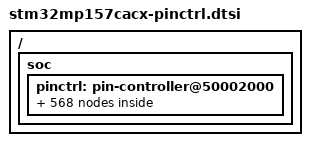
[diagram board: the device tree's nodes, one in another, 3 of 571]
/*
 * NOTE: Autogenerated file using genpinctrl.py
 *
 * SPDX-License-Identifier: Apache-2.0
 */

#include <dt-bindings/pinctrl/stm32-pinctrl.h>

/ {
	soc {
		pinctrl: pin-controller@50002000 {

			/* ADC_IN / ADC_INN / ADC_INP */

			adc1_inp16_pa0: adc1_inp16_pa0 {
				pinmux = <STM32_PINMUX('A', 0, ANALOG)>;
			};

			adc1_inn16_pa1: adc1_inn16_pa1 {
				pinmux = <STM32_PINMUX('A', 1, ANALOG)>;
			};

			adc1_inp17_pa1: adc1_inp17_pa1 {
				pinmux = <STM32_PINMUX('A', 1, ANALOG)>;
			};

			adc1_inp14_pa2: adc1_inp14_pa2 {
				pinmux = <STM32_PINMUX('A', 2, ANALOG)>;
			};

			adc1_inp15_pa3: adc1_inp15_pa3 {
				pinmux = <STM32_PINMUX('A', 3, ANALOG)>;
			};

			adc1_inp18_pa4: adc1_inp18_pa4 {
				pinmux = <STM32_PINMUX('A', 4, ANALOG)>;
			};

			adc1_inn18_pa5: adc1_inn18_pa5 {
				pinmux = <STM32_PINMUX('A', 5, ANALOG)>;
			};

			adc1_inp19_pa5: adc1_inp19_pa5 {
				pinmux = <STM32_PINMUX('A', 5, ANALOG)>;
			};

			adc1_inp3_pa6: adc1_inp3_pa6 {
				pinmux = <STM32_PINMUX('A', 6, ANALOG)>;
			};

			adc1_inn3_pa7: adc1_inn3_pa7 {
				pinmux = <STM32_PINMUX('A', 7, ANALOG)>;
			};

			adc1_inp7_pa7: adc1_inp7_pa7 {
				pinmux = <STM32_PINMUX('A', 7, ANALOG)>;
			};

			adc1_inn5_pb0: adc1_inn5_pb0 {
				pinmux = <STM32_PINMUX('B', 0, ANALOG)>;
			};

			adc1_inp9_pb0: adc1_inp9_pb0 {
				pinmux = <STM32_PINMUX('B', 0, ANALOG)>;
			};

			adc1_inp5_pb1: adc1_inp5_pb1 {
				pinmux = <STM32_PINMUX('B', 1, ANALOG)>;
			};

			adc1_inp10_pc0: adc1_inp10_pc0 {
				pinmux = <STM32_PINMUX('C', 0, ANALOG)>;
			};

			adc1_inn10_pc1: adc1_inn10_pc1 {
				pinmux = <STM32_PINMUX('C', 1, ANALOG)>;
			};

			adc1_inp11_pc1: adc1_inp11_pc1 {
				pinmux = <STM32_PINMUX('C', 1, ANALOG)>;
			};

			adc1_inn11_pc2: adc1_inn11_pc2 {
				pinmux = <STM32_PINMUX('C', 2, ANALOG)>;
			};

			adc1_inp12_pc2: adc1_inp12_pc2 {
				pinmux = <STM32_PINMUX('C', 2, ANALOG)>;
			};

			adc1_inn12_pc3: adc1_inn12_pc3 {
				pinmux = <STM32_PINMUX('C', 3, ANALOG)>;
			};

			adc1_inp13_pc3: adc1_inp13_pc3 {
				pinmux = <STM32_PINMUX('C', 3, ANALOG)>;
			};

			adc1_inp4_pc4: adc1_inp4_pc4 {
				pinmux = <STM32_PINMUX('C', 4, ANALOG)>;
			};

			adc1_inn4_pc5: adc1_inn4_pc5 {
				pinmux = <STM32_PINMUX('C', 5, ANALOG)>;
			};

			adc1_inp8_pc5: adc1_inp8_pc5 {
				pinmux = <STM32_PINMUX('C', 5, ANALOG)>;
			};

			adc1_inp2_pf11: adc1_inp2_pf11 {
				pinmux = <STM32_PINMUX('F', 11, ANALOG)>;
			};

			adc1_inn2_pf12: adc1_inn2_pf12 {
				pinmux = <STM32_PINMUX('F', 12, ANALOG)>;
			};

			adc1_inp6_pf12: adc1_inp6_pf12 {
				pinmux = <STM32_PINMUX('F', 12, ANALOG)>;
			};

			adc2_inp18_pa4: adc2_inp18_pa4 {
				pinmux = <STM32_PINMUX('A', 4, ANALOG)>;
			};

			adc2_inn18_pa5: adc2_inn18_pa5 {
				pinmux = <STM32_PINMUX('A', 5, ANALOG)>;
			};

			adc2_inp19_pa5: adc2_inp19_pa5 {
				pinmux = <STM32_PINMUX('A', 5, ANALOG)>;
			};

			adc2_inp3_pa6: adc2_inp3_pa6 {
				pinmux = <STM32_PINMUX('A', 6, ANALOG)>;
			};

			adc2_inn3_pa7: adc2_inn3_pa7 {
				pinmux = <STM32_PINMUX('A', 7, ANALOG)>;
			};

			adc2_inp7_pa7: adc2_inp7_pa7 {
				pinmux = <STM32_PINMUX('A', 7, ANALOG)>;
			};

			adc2_inn5_pb0: adc2_inn5_pb0 {
				pinmux = <STM32_PINMUX('B', 0, ANALOG)>;
			};

			adc2_inp9_pb0: adc2_inp9_pb0 {
				pinmux = <STM32_PINMUX('B', 0, ANALOG)>;
			};

			adc2_inp5_pb1: adc2_inp5_pb1 {
				pinmux = <STM32_PINMUX('B', 1, ANALOG)>;
			};

			adc2_inp10_pc0: adc2_inp10_pc0 {
				pinmux = <STM32_PINMUX('C', 0, ANALOG)>;
			};

			adc2_inn10_pc1: adc2_inn10_pc1 {
				pinmux = <STM32_PINMUX('C', 1, ANALOG)>;
			};

			adc2_inp11_pc1: adc2_inp11_pc1 {
				pinmux = <STM32_PINMUX('C', 1, ANALOG)>;
			};

			adc2_inp4_pc4: adc2_inp4_pc4 {
				pinmux = <STM32_PINMUX('C', 4, ANALOG)>;
			};

			adc2_inn4_pc5: adc2_inn4_pc5 {
				pinmux = <STM32_PINMUX('C', 5, ANALOG)>;
			};

			adc2_inp8_pc5: adc2_inp8_pc5 {
				pinmux = <STM32_PINMUX('C', 5, ANALOG)>;
			};

			adc2_inp2_pf13: adc2_inp2_pf13 {
				pinmux = <STM32_PINMUX('F', 13, ANALOG)>;
			};

			adc2_inn2_pf14: adc2_inn2_pf14 {
				pinmux = <STM32_PINMUX('F', 14, ANALOG)>;
			};

			adc2_inp6_pf14: adc2_inp6_pf14 {
				pinmux = <STM32_PINMUX('F', 14, ANALOG)>;
			};

			/* DAC_OUT */

			dac1_out1_pa4: dac1_out1_pa4 {
				pinmux = <STM32_PINMUX('A', 4, ANALOG)>;
			};

			dac1_out2_pa5: dac1_out2_pa5 {
				pinmux = <STM32_PINMUX('A', 5, ANALOG)>;
			};

			/* FDCAN_RX */

			fdcan1_rx_pa11: fdcan1_rx_pa11 {
				pinmux = <STM32_PINMUX('A', 11, AF9)>;
			};

			fdcan1_rx_pb8: fdcan1_rx_pb8 {
				pinmux = <STM32_PINMUX('B', 8, AF9)>;
			};

			fdcan1_rx_pd0: fdcan1_rx_pd0 {
				pinmux = <STM32_PINMUX('D', 0, AF9)>;
			};

			fdcan1_rx_ph14: fdcan1_rx_ph14 {
				pinmux = <STM32_PINMUX('H', 14, AF9)>;
			};

			fdcan1_rx_pi9: fdcan1_rx_pi9 {
				pinmux = <STM32_PINMUX('I', 9, AF9)>;
			};

			fdcan2_rx_pb5: fdcan2_rx_pb5 {
				pinmux = <STM32_PINMUX('B', 5, AF9)>;
			};

			fdcan2_rx_pb12: fdcan2_rx_pb12 {
				pinmux = <STM32_PINMUX('B', 12, AF9)>;
			};

			/* FDCAN_TX */

			fdcan1_tx_pa12: fdcan1_tx_pa12 {
				pinmux = <STM32_PINMUX('A', 12, AF9)>;
			};

			fdcan1_tx_pb9: fdcan1_tx_pb9 {
				pinmux = <STM32_PINMUX('B', 9, AF9)>;
			};

			fdcan1_tx_pd1: fdcan1_tx_pd1 {
				pinmux = <STM32_PINMUX('D', 1, AF9)>;
			};

			fdcan1_tx_ph13: fdcan1_tx_ph13 {
				pinmux = <STM32_PINMUX('H', 13, AF9)>;
			};

			fdcan2_tx_pb6: fdcan2_tx_pb6 {
				pinmux = <STM32_PINMUX('B', 6, AF9)>;
			};

			fdcan2_tx_pb13: fdcan2_tx_pb13 {
				pinmux = <STM32_PINMUX('B', 13, AF9)>;
			};

			/* FMC */

			fmc_nl_pb7: fmc_nl_pb7 {
				pinmux = <STM32_PINMUX('B', 7, AF12)>;
				bias-pull-up;
				slew-rate = "very-high-speed";
			};

			fmc_d2_pd0: fmc_d2_pd0 {
				pinmux = <STM32_PINMUX('D', 0, AF12)>;
				bias-pull-up;
				slew-rate = "very-high-speed";
			};

			fmc_d3_pd1: fmc_d3_pd1 {
				pinmux = <STM32_PINMUX('D', 1, AF12)>;
				bias-pull-up;
				slew-rate = "very-high-speed";
			};

			fmc_clk_pd3: fmc_clk_pd3 {
				pinmux = <STM32_PINMUX('D', 3, AF12)>;
				bias-pull-up;
				slew-rate = "very-high-speed";
			};

			fmc_noe_pd4: fmc_noe_pd4 {
				pinmux = <STM32_PINMUX('D', 4, AF12)>;
				bias-pull-up;
				slew-rate = "very-high-speed";
			};

			fmc_nwe_pd5: fmc_nwe_pd5 {
				pinmux = <STM32_PINMUX('D', 5, AF12)>;
				bias-pull-up;
				slew-rate = "very-high-speed";
			};

			fmc_nwait_pd6: fmc_nwait_pd6 {
				pinmux = <STM32_PINMUX('D', 6, AF12)>;
				bias-pull-up;
				slew-rate = "very-high-speed";
			};

			fmc_ne1_pd7: fmc_ne1_pd7 {
				pinmux = <STM32_PINMUX('D', 7, AF12)>;
				bias-pull-up;
				slew-rate = "very-high-speed";
			};

			fmc_d13_pd8: fmc_d13_pd8 {
				pinmux = <STM32_PINMUX('D', 8, AF12)>;
				bias-pull-up;
				slew-rate = "very-high-speed";
			};

			fmc_d14_pd9: fmc_d14_pd9 {
				pinmux = <STM32_PINMUX('D', 9, AF12)>;
				bias-pull-up;
				slew-rate = "very-high-speed";
			};

			fmc_d15_pd10: fmc_d15_pd10 {
				pinmux = <STM32_PINMUX('D', 10, AF12)>;
				bias-pull-up;
				slew-rate = "very-high-speed";
			};

			fmc_a16_pd11: fmc_a16_pd11 {
				pinmux = <STM32_PINMUX('D', 11, AF12)>;
				bias-pull-up;
				slew-rate = "very-high-speed";
			};

			fmc_a17_pd12: fmc_a17_pd12 {
				pinmux = <STM32_PINMUX('D', 12, AF12)>;
				bias-pull-up;
				slew-rate = "very-high-speed";
			};

			fmc_a18_pd13: fmc_a18_pd13 {
				pinmux = <STM32_PINMUX('D', 13, AF12)>;
				bias-pull-up;
				slew-rate = "very-high-speed";
			};

			fmc_d0_pd14: fmc_d0_pd14 {
				pinmux = <STM32_PINMUX('D', 14, AF12)>;
				bias-pull-up;
				slew-rate = "very-high-speed";
			};

			fmc_d1_pd15: fmc_d1_pd15 {
				pinmux = <STM32_PINMUX('D', 15, AF12)>;
				bias-pull-up;
				slew-rate = "very-high-speed";
			};

			fmc_nbl0_pe0: fmc_nbl0_pe0 {
				pinmux = <STM32_PINMUX('E', 0, AF12)>;
				bias-pull-up;
				slew-rate = "very-high-speed";
			};

			fmc_nbl1_pe1: fmc_nbl1_pe1 {
				pinmux = <STM32_PINMUX('E', 1, AF12)>;
				bias-pull-up;
				slew-rate = "very-high-speed";
			};

			fmc_a23_pe2: fmc_a23_pe2 {
				pinmux = <STM32_PINMUX('E', 2, AF12)>;
				bias-pull-up;
				slew-rate = "very-high-speed";
			};

			fmc_a19_pe3: fmc_a19_pe3 {
				pinmux = <STM32_PINMUX('E', 3, AF12)>;
				bias-pull-up;
				slew-rate = "very-high-speed";
			};

			fmc_a20_pe4: fmc_a20_pe4 {
				pinmux = <STM32_PINMUX('E', 4, AF12)>;
				bias-pull-up;
				slew-rate = "very-high-speed";
			};

			fmc_a21_pe5: fmc_a21_pe5 {
				pinmux = <STM32_PINMUX('E', 5, AF12)>;
				bias-pull-up;
				slew-rate = "very-high-speed";
			};

			fmc_a22_pe6: fmc_a22_pe6 {
				pinmux = <STM32_PINMUX('E', 6, AF12)>;
				bias-pull-up;
				slew-rate = "very-high-speed";
			};

			fmc_d4_pe7: fmc_d4_pe7 {
				pinmux = <STM32_PINMUX('E', 7, AF12)>;
				bias-pull-up;
				slew-rate = "very-high-speed";
			};

			fmc_d5_pe8: fmc_d5_pe8 {
				pinmux = <STM32_PINMUX('E', 8, AF12)>;
				bias-pull-up;
				slew-rate = "very-high-speed";
			};

			fmc_d6_pe9: fmc_d6_pe9 {
				pinmux = <STM32_PINMUX('E', 9, AF12)>;
				bias-pull-up;
				slew-rate = "very-high-speed";
			};

			fmc_d7_pe10: fmc_d7_pe10 {
				pinmux = <STM32_PINMUX('E', 10, AF12)>;
				bias-pull-up;
				slew-rate = "very-high-speed";
			};

			fmc_d8_pe11: fmc_d8_pe11 {
				pinmux = <STM32_PINMUX('E', 11, AF12)>;
				bias-pull-up;
				slew-rate = "very-high-speed";
			};

			fmc_d9_pe12: fmc_d9_pe12 {
				pinmux = <STM32_PINMUX('E', 12, AF12)>;
				bias-pull-up;
				slew-rate = "very-high-speed";
			};

			fmc_d10_pe13: fmc_d10_pe13 {
				pinmux = <STM32_PINMUX('E', 13, AF12)>;
				bias-pull-up;
				slew-rate = "very-high-speed";
			};

			fmc_d11_pe14: fmc_d11_pe14 {
				pinmux = <STM32_PINMUX('E', 14, AF12)>;
				bias-pull-up;
				slew-rate = "very-high-speed";
			};

			fmc_d12_pe15: fmc_d12_pe15 {
				pinmux = <STM32_PINMUX('E', 15, AF12)>;
				bias-pull-up;
				slew-rate = "very-high-speed";
			};

			fmc_a0_pf0: fmc_a0_pf0 {
				pinmux = <STM32_PINMUX('F', 0, AF12)>;
				bias-pull-up;
				slew-rate = "very-high-speed";
			};

			fmc_a1_pf1: fmc_a1_pf1 {
				pinmux = <STM32_PINMUX('F', 1, AF12)>;
				bias-pull-up;
				slew-rate = "very-high-speed";
			};

			fmc_a2_pf2: fmc_a2_pf2 {
				pinmux = <STM32_PINMUX('F', 2, AF12)>;
				bias-pull-up;
				slew-rate = "very-high-speed";
			};

			fmc_a3_pf3: fmc_a3_pf3 {
				pinmux = <STM32_PINMUX('F', 3, AF12)>;
				bias-pull-up;
				slew-rate = "very-high-speed";
			};

			fmc_a4_pf4: fmc_a4_pf4 {
				pinmux = <STM32_PINMUX('F', 4, AF12)>;
				bias-pull-up;
				slew-rate = "very-high-speed";
			};

			fmc_a5_pf5: fmc_a5_pf5 {
				pinmux = <STM32_PINMUX('F', 5, AF12)>;
				bias-pull-up;
				slew-rate = "very-high-speed";
			};

			fmc_a6_pf12: fmc_a6_pf12 {
				pinmux = <STM32_PINMUX('F', 12, AF12)>;
				bias-pull-up;
				slew-rate = "very-high-speed";
			};

			fmc_a7_pf13: fmc_a7_pf13 {
				pinmux = <STM32_PINMUX('F', 13, AF12)>;
				bias-pull-up;
				slew-rate = "very-high-speed";
			};

			fmc_a8_pf14: fmc_a8_pf14 {
				pinmux = <STM32_PINMUX('F', 14, AF12)>;
				bias-pull-up;
				slew-rate = "very-high-speed";
			};

			fmc_a9_pf15: fmc_a9_pf15 {
				pinmux = <STM32_PINMUX('F', 15, AF12)>;
				bias-pull-up;
				slew-rate = "very-high-speed";
			};

			fmc_a10_pg0: fmc_a10_pg0 {
				pinmux = <STM32_PINMUX('G', 0, AF12)>;
				bias-pull-up;
				slew-rate = "very-high-speed";
			};

			fmc_a11_pg1: fmc_a11_pg1 {
				pinmux = <STM32_PINMUX('G', 1, AF12)>;
				bias-pull-up;
				slew-rate = "very-high-speed";
			};

			fmc_a12_pg2: fmc_a12_pg2 {
				pinmux = <STM32_PINMUX('G', 2, AF12)>;
				bias-pull-up;
				slew-rate = "very-high-speed";
			};

			fmc_a13_pg3: fmc_a13_pg3 {
				pinmux = <STM32_PINMUX('G', 3, AF12)>;
				bias-pull-up;
				slew-rate = "very-high-speed";
			};

			fmc_a14_pg4: fmc_a14_pg4 {
				pinmux = <STM32_PINMUX('G', 4, AF12)>;
				bias-pull-up;
				slew-rate = "very-high-speed";
			};

			fmc_a15_pg5: fmc_a15_pg5 {
				pinmux = <STM32_PINMUX('G', 5, AF12)>;
				bias-pull-up;
				slew-rate = "very-high-speed";
			};

			fmc_nce_pg9: fmc_nce_pg9 {
				pinmux = <STM32_PINMUX('G', 9, AF12)>;
				bias-pull-up;
				slew-rate = "very-high-speed";
			};

			fmc_ne2_pg9: fmc_ne2_pg9 {
				pinmux = <STM32_PINMUX('G', 9, AF12)>;
				bias-pull-up;
				slew-rate = "very-high-speed";
			};

			fmc_ne3_pg10: fmc_ne3_pg10 {
				pinmux = <STM32_PINMUX('G', 10, AF12)>;
				bias-pull-up;
				slew-rate = "very-high-speed";
			};

			fmc_ne4_pg12: fmc_ne4_pg12 {
				pinmux = <STM32_PINMUX('G', 12, AF12)>;
				bias-pull-up;
				slew-rate = "very-high-speed";
			};

			fmc_a24_pg13: fmc_a24_pg13 {
				pinmux = <STM32_PINMUX('G', 13, AF12)>;
				bias-pull-up;
				slew-rate = "very-high-speed";
			};

			fmc_a25_pg14: fmc_a25_pg14 {
				pinmux = <STM32_PINMUX('G', 14, AF12)>;
				bias-pull-up;
				slew-rate = "very-high-speed";
			};

			/* I2C_SCL */

			i2c1_scl_pb6: i2c1_scl_pb6 {
				pinmux = <STM32_PINMUX('B', 6, AF4)>;
				bias-pull-up;
				drive-open-drain;
			};

			i2c1_scl_pb8: i2c1_scl_pb8 {
				pinmux = <STM32_PINMUX('B', 8, AF4)>;
				bias-pull-up;
				drive-open-drain;
			};

			i2c1_scl_pd12: i2c1_scl_pd12 {
				pinmux = <STM32_PINMUX('D', 12, AF5)>;
				bias-pull-up;
				drive-open-drain;
			};

			i2c1_scl_pf14: i2c1_scl_pf14 {
				pinmux = <STM32_PINMUX('F', 14, AF5)>;
				bias-pull-up;
				drive-open-drain;
			};

			i2c1_scl_ph11: i2c1_scl_ph11 {
				pinmux = <STM32_PINMUX('H', 11, AF5)>;
				bias-pull-up;
				drive-open-drain;
			};

			i2c2_scl_pb10: i2c2_scl_pb10 {
				pinmux = <STM32_PINMUX('B', 10, AF4)>;
				bias-pull-up;
				drive-open-drain;
			};

			i2c2_scl_pd7: i2c2_scl_pd7 {
				pinmux = <STM32_PINMUX('D', 7, AF4)>;
				bias-pull-up;
				drive-open-drain;
			};

			i2c2_scl_pf1: i2c2_scl_pf1 {
				pinmux = <STM32_PINMUX('F', 1, AF4)>;
				bias-pull-up;
				drive-open-drain;
			};

			i2c2_scl_ph4: i2c2_scl_ph4 {
				pinmux = <STM32_PINMUX('H', 4, AF4)>;
				bias-pull-up;
				drive-open-drain;
			};

			i2c2_scl_pz0: i2c2_scl_pz0 {
				pinmux = <STM32_PINMUX('Z', 0, AF3)>;
				bias-pull-up;
				drive-open-drain;
			};

			i2c2_scl_pz2: i2c2_scl_pz2 {
				pinmux = <STM32_PINMUX('Z', 2, AF3)>;
				bias-pull-up;
				drive-open-drain;
			};

			i2c2_scl_pz4: i2c2_scl_pz4 {
				pinmux = <STM32_PINMUX('Z', 4, AF3)>;
				bias-pull-up;
				drive-open-drain;
			};

			i2c2_scl_pz6: i2c2_scl_pz6 {
				pinmux = <STM32_PINMUX('Z', 6, AF3)>;
				bias-pull-up;
				drive-open-drain;
			};

			i2c3_scl_pa8: i2c3_scl_pa8 {
				pinmux = <STM32_PINMUX('A', 8, AF4)>;
				bias-pull-up;
				drive-open-drain;
			};

			i2c3_scl_ph7: i2c3_scl_ph7 {
				pinmux = <STM32_PINMUX('H', 7, AF4)>;
				bias-pull-up;
				drive-open-drain;
			};

			i2c4_scl_pb6: i2c4_scl_pb6 {
				pinmux = <STM32_PINMUX('B', 6, AF6)>;
				bias-pull-up;
				drive-open-drain;
			};

			i2c4_scl_pb8: i2c4_scl_pb8 {
				pinmux = <STM32_PINMUX('B', 8, AF6)>;
				bias-pull-up;
				drive-open-drain;
			};

			i2c4_scl_pd12: i2c4_scl_pd12 {
				pinmux = <STM32_PINMUX('D', 12, AF4)>;
				bias-pull-up;
				drive-open-drain;
			};

			i2c4_scl_pe2: i2c4_scl_pe2 {
				pinmux = <STM32_PINMUX('E', 2, AF4)>;
				bias-pull-up;
				drive-open-drain;
			};

			i2c4_scl_pf14: i2c4_scl_pf14 {
				pinmux = <STM32_PINMUX('F', 14, AF4)>;
				bias-pull-up;
				drive-open-drain;
			};

			i2c4_scl_ph11: i2c4_scl_ph11 {
				pinmux = <STM32_PINMUX('H', 11, AF4)>;
				bias-pull-up;
				drive-open-drain;
			};

			i2c4_scl_pz4: i2c4_scl_pz4 {
				pinmux = <STM32_PINMUX('Z', 4, AF6)>;
				bias-pull-up;
				drive-open-drain;
			};

			i2c5_scl_pa11: i2c5_scl_pa11 {
				pinmux = <STM32_PINMUX('A', 11, AF4)>;
				bias-pull-up;
				drive-open-drain;
			};

			i2c5_scl_pd1: i2c5_scl_pd1 {
				pinmux = <STM32_PINMUX('D', 1, AF4)>;
				bias-pull-up;
				drive-open-drain;
			};

			i2c5_scl_pz4: i2c5_scl_pz4 {
				pinmux = <STM32_PINMUX('Z', 4, AF4)>;
				bias-pull-up;
				drive-open-drain;
			};

			i2c6_scl_pa11: i2c6_scl_pa11 {
				pinmux = <STM32_PINMUX('A', 11, AF2)>;
				bias-pull-up;
				drive-open-drain;
			};

			i2c6_scl_pd1: i2c6_scl_pd1 {
				pinmux = <STM32_PINMUX('D', 1, AF2)>;
				bias-pull-up;
				drive-open-drain;
			};

			i2c6_scl_pz0: i2c6_scl_pz0 {
				pinmux = <STM32_PINMUX('Z', 0, AF2)>;
				bias-pull-up;
				drive-open-drain;
			};

			i2c6_scl_pz2: i2c6_scl_pz2 {
				pinmux = <STM32_PINMUX('Z', 2, AF2)>;
				bias-pull-up;
				drive-open-drain;
			};

			i2c6_scl_pz4: i2c6_scl_pz4 {
				pinmux = <STM32_PINMUX('Z', 4, AF2)>;
				bias-pull-up;
				drive-open-drain;
			};

			i2c6_scl_pz6: i2c6_scl_pz6 {
				pinmux = <STM32_PINMUX('Z', 6, AF2)>;
				bias-pull-up;
				drive-open-drain;
			};

			/* I2C_SDA */

			i2c1_sda_pb7: i2c1_sda_pb7 {
				pinmux = <STM32_PINMUX('B', 7, AF4)>;
				bias-pull-up;
				drive-open-drain;
			};

			i2c1_sda_pb9: i2c1_sda_pb9 {
				pinmux = <STM32_PINMUX('B', 9, AF4)>;
				bias-pull-up;
				drive-open-drain;
			};

			i2c1_sda_pd13: i2c1_sda_pd13 {
				pinmux = <STM32_PINMUX('D', 13, AF5)>;
				bias-pull-up;
				drive-open-drain;
			};

			i2c1_sda_pf15: i2c1_sda_pf15 {
				pinmux = <STM32_PINMUX('F', 15, AF5)>;
				bias-pull-up;
				drive-open-drain;
			};

			i2c1_sda_ph12: i2c1_sda_ph12 {
				pinmux = <STM32_PINMUX('H', 12, AF5)>;
				bias-pull-up;
				drive-open-drain;
			};

			i2c2_sda_pb11: i2c2_sda_pb11 {
				pinmux = <STM32_PINMUX('B', 11, AF4)>;
				bias-pull-up;
				drive-open-drain;
			};

			i2c2_sda_pf0: i2c2_sda_pf0 {
				pinmux = <STM32_PINMUX('F', 0, AF4)>;
				bias-pull-up;
				drive-open-drain;
			};

			i2c2_sda_pg15: i2c2_sda_pg15 {
				pinmux = <STM32_PINMUX('G', 15, AF4)>;
				bias-pull-up;
				drive-open-drain;
			};

			i2c2_sda_ph5: i2c2_sda_ph5 {
				pinmux = <STM32_PINMUX('H', 5, AF4)>;
				bias-pull-up;
				drive-open-drain;
			};

			i2c2_sda_pz1: i2c2_sda_pz1 {
				pinmux = <STM32_PINMUX('Z', 1, AF3)>;
				bias-pull-up;
				drive-open-drain;
			};

			i2c2_sda_pz3: i2c2_sda_pz3 {
				pinmux = <STM32_PINMUX('Z', 3, AF3)>;
				bias-pull-up;
				drive-open-drain;
			};

			i2c2_sda_pz5: i2c2_sda_pz5 {
				pinmux = <STM32_PINMUX('Z', 5, AF3)>;
				bias-pull-up;
				drive-open-drain;
			};

			i2c2_sda_pz7: i2c2_sda_pz7 {
				pinmux = <STM32_PINMUX('Z', 7, AF3)>;
				bias-pull-up;
				drive-open-drain;
			};

			i2c3_sda_pc9: i2c3_sda_pc9 {
				pinmux = <STM32_PINMUX('C', 9, AF4)>;
				bias-pull-up;
				drive-open-drain;
			};

			i2c3_sda_ph8: i2c3_sda_ph8 {
				pinmux = <STM32_PINMUX('H', 8, AF4)>;
				bias-pull-up;
				drive-open-drain;
			};

			i2c4_sda_pb7: i2c4_sda_pb7 {
				pinmux = <STM32_PINMUX('B', 7, AF6)>;
				bias-pull-up;
				drive-open-drain;
			};

			i2c4_sda_pb9: i2c4_sda_pb9 {
				pinmux = <STM32_PINMUX('B', 9, AF6)>;
				bias-pull-up;
				drive-open-drain;
			};

			i2c4_sda_pd13: i2c4_sda_pd13 {
				pinmux = <STM32_PINMUX('D', 13, AF4)>;
				bias-pull-up;
				drive-open-drain;
			};

			i2c4_sda_pf15: i2c4_sda_pf15 {
				pinmux = <STM32_PINMUX('F', 15, AF4)>;
				bias-pull-up;
				drive-open-drain;
			};

			i2c4_sda_ph12: i2c4_sda_ph12 {
				pinmux = <STM32_PINMUX('H', 12, AF4)>;
				bias-pull-up;
				drive-open-drain;
			};

			i2c4_sda_pz1: i2c4_sda_pz1 {
				pinmux = <STM32_PINMUX('Z', 1, AF6)>;
				bias-pull-up;
				drive-open-drain;
			};

			i2c4_sda_pz3: i2c4_sda_pz3 {
				pinmux = <STM32_PINMUX('Z', 3, AF6)>;
				bias-pull-up;
				drive-open-drain;
			};

			i2c4_sda_pz5: i2c4_sda_pz5 {
				pinmux = <STM32_PINMUX('Z', 5, AF6)>;
				bias-pull-up;
				drive-open-drain;
			};

			i2c5_sda_pa12: i2c5_sda_pa12 {
				pinmux = <STM32_PINMUX('A', 12, AF4)>;
				bias-pull-up;
				drive-open-drain;
			};

			i2c5_sda_pd0: i2c5_sda_pd0 {
				pinmux = <STM32_PINMUX('D', 0, AF4)>;
				bias-pull-up;
				drive-open-drain;
			};

			i2c5_sda_pz1: i2c5_sda_pz1 {
				pinmux = <STM32_PINMUX('Z', 1, AF4)>;
				bias-pull-up;
				drive-open-drain;
			};

			i2c5_sda_pz3: i2c5_sda_pz3 {
				pinmux = <STM32_PINMUX('Z', 3, AF4)>;
				bias-pull-up;
				drive-open-drain;
			};

			i2c5_sda_pz5: i2c5_sda_pz5 {
				pinmux = <STM32_PINMUX('Z', 5, AF4)>;
				bias-pull-up;
				drive-open-drain;
			};

			i2c6_sda_pa12: i2c6_sda_pa12 {
				pinmux = <STM32_PINMUX('A', 12, AF2)>;
				bias-pull-up;
				drive-open-drain;
			};

			i2c6_sda_pd0: i2c6_sda_pd0 {
				pinmux = <STM32_PINMUX('D', 0, AF2)>;
				bias-pull-up;
				drive-open-drain;
			};

			i2c6_sda_pz1: i2c6_sda_pz1 {
				pinmux = <STM32_PINMUX('Z', 1, AF2)>;
				bias-pull-up;
				drive-open-drain;
			};

			i2c6_sda_pz3: i2c6_sda_pz3 {
				pinmux = <STM32_PINMUX('Z', 3, AF2)>;
				bias-pull-up;
				drive-open-drain;
			};

			i2c6_sda_pz5: i2c6_sda_pz5 {
				pinmux = <STM32_PINMUX('Z', 5, AF2)>;
				bias-pull-up;
				drive-open-drain;
			};

			i2c6_sda_pz7: i2c6_sda_pz7 {
				pinmux = <STM32_PINMUX('Z', 7, AF2)>;
				bias-pull-up;
				drive-open-drain;
			};

			/* I2S_CK */

			i2s1_ck_pa5: i2s1_ck_pa5 {
				pinmux = <STM32_PINMUX('A', 5, AF5)>;
				slew-rate = "very-high-speed";
			};

			i2s1_ck_pb3: i2s1_ck_pb3 {
				pinmux = <STM32_PINMUX('B', 3, AF5)>;
				slew-rate = "very-high-speed";
			};

			i2s1_ck_pz0: i2s1_ck_pz0 {
				pinmux = <STM32_PINMUX('Z', 0, AF5)>;
				slew-rate = "very-high-speed";
			};

			i2s2_ck_pa9: i2s2_ck_pa9 {
				pinmux = <STM32_PINMUX('A', 9, AF5)>;
				slew-rate = "very-high-speed";
			};

			i2s2_ck_pb10: i2s2_ck_pb10 {
				pinmux = <STM32_PINMUX('B', 10, AF5)>;
				slew-rate = "very-high-speed";
			};

			i2s2_ck_pb13: i2s2_ck_pb13 {
				pinmux = <STM32_PINMUX('B', 13, AF5)>;
				slew-rate = "very-high-speed";
			};

			i2s2_ck_pd3: i2s2_ck_pd3 {
				pinmux = <STM32_PINMUX('D', 3, AF5)>;
				slew-rate = "very-high-speed";
			};

			i2s2_ck_pi1: i2s2_ck_pi1 {
				pinmux = <STM32_PINMUX('I', 1, AF5)>;
				slew-rate = "very-high-speed";
			};

			i2s3_ck_pb3: i2s3_ck_pb3 {
				pinmux = <STM32_PINMUX('B', 3, AF6)>;
				slew-rate = "very-high-speed";
			};

			i2s3_ck_pc10: i2s3_ck_pc10 {
				pinmux = <STM32_PINMUX('C', 10, AF6)>;
				slew-rate = "very-high-speed";
			};

			i2s3_ck_pe0: i2s3_ck_pe0 {
				pinmux = <STM32_PINMUX('E', 0, AF5)>;
				slew-rate = "very-high-speed";
			};

			/* I2S_WS */

			i2s1_ws_pa4: i2s1_ws_pa4 {
				pinmux = <STM32_PINMUX('A', 4, AF5)>;
			};

			i2s1_ws_pa15: i2s1_ws_pa15 {
				pinmux = <STM32_PINMUX('A', 15, AF5)>;
			};

			i2s1_ws_pz3: i2s1_ws_pz3 {
				pinmux = <STM32_PINMUX('Z', 3, AF5)>;
			};

			i2s2_ws_pa11: i2s2_ws_pa11 {
				pinmux = <STM32_PINMUX('A', 11, AF5)>;
			};

			i2s2_ws_pb4: i2s2_ws_pb4 {
				pinmux = <STM32_PINMUX('B', 4, AF7)>;
			};

			i2s2_ws_pb9: i2s2_ws_pb9 {
				pinmux = <STM32_PINMUX('B', 9, AF5)>;
			};

			i2s2_ws_pb12: i2s2_ws_pb12 {
				pinmux = <STM32_PINMUX('B', 12, AF5)>;
			};

			i2s2_ws_pi0: i2s2_ws_pi0 {
				pinmux = <STM32_PINMUX('I', 0, AF5)>;
			};

			i2s3_ws_pa4: i2s3_ws_pa4 {
				pinmux = <STM32_PINMUX('A', 4, AF6)>;
			};

			i2s3_ws_pa10: i2s3_ws_pa10 {
				pinmux = <STM32_PINMUX('A', 10, AF5)>;
			};

			i2s3_ws_pa15: i2s3_ws_pa15 {
				pinmux = <STM32_PINMUX('A', 15, AF6)>;
			};

			/* QUADSPI */

			quadspi_bk1_io3_pa1: quadspi_bk1_io3_pa1 {
				pinmux = <STM32_PINMUX('A', 1, AF9)>;
				slew-rate = "very-high-speed";
			};

			quadspi_clk_pa7: quadspi_clk_pa7 {
				pinmux = <STM32_PINMUX('A', 7, AF10)>;
				slew-rate = "very-high-speed";
			};

			quadspi_clk_pb2: quadspi_clk_pb2 {
				pinmux = <STM32_PINMUX('B', 2, AF9)>;
				slew-rate = "very-high-speed";
			};

			quadspi_bk1_ncs_pb6: quadspi_bk1_ncs_pb6 {
				pinmux = <STM32_PINMUX('B', 6, AF10)>;
				slew-rate = "very-high-speed";
			};

			quadspi_bk1_ncs_pb10: quadspi_bk1_ncs_pb10 {
				pinmux = <STM32_PINMUX('B', 10, AF9)>;
				slew-rate = "very-high-speed";
			};

			quadspi_bk2_ncs_pc0: quadspi_bk2_ncs_pc0 {
				pinmux = <STM32_PINMUX('C', 0, AF10)>;
				slew-rate = "very-high-speed";
			};

			quadspi_bk1_io0_pc9: quadspi_bk1_io0_pc9 {
				pinmux = <STM32_PINMUX('C', 9, AF9)>;
				slew-rate = "very-high-speed";
			};

			quadspi_bk1_io1_pc10: quadspi_bk1_io1_pc10 {
				pinmux = <STM32_PINMUX('C', 10, AF9)>;
				slew-rate = "very-high-speed";
			};

			quadspi_bk2_ncs_pc11: quadspi_bk2_ncs_pc11 {
				pinmux = <STM32_PINMUX('C', 11, AF9)>;
				slew-rate = "very-high-speed";
			};

			quadspi_bk1_io0_pd11: quadspi_bk1_io0_pd11 {
				pinmux = <STM32_PINMUX('D', 11, AF9)>;
				slew-rate = "very-high-speed";
			};

			quadspi_bk1_io1_pd12: quadspi_bk1_io1_pd12 {
				pinmux = <STM32_PINMUX('D', 12, AF9)>;
				slew-rate = "very-high-speed";
			};

			quadspi_bk1_io3_pd13: quadspi_bk1_io3_pd13 {
				pinmux = <STM32_PINMUX('D', 13, AF9)>;
				slew-rate = "very-high-speed";
			};

			quadspi_bk1_io2_pe2: quadspi_bk1_io2_pe2 {
				pinmux = <STM32_PINMUX('E', 2, AF9)>;
				slew-rate = "very-high-speed";
			};

			quadspi_bk2_io0_pe7: quadspi_bk2_io0_pe7 {
				pinmux = <STM32_PINMUX('E', 7, AF10)>;
				slew-rate = "very-high-speed";
			};

			quadspi_bk2_io1_pe8: quadspi_bk2_io1_pe8 {
				pinmux = <STM32_PINMUX('E', 8, AF10)>;
				slew-rate = "very-high-speed";
			};

			quadspi_bk2_io2_pe9: quadspi_bk2_io2_pe9 {
				pinmux = <STM32_PINMUX('E', 9, AF10)>;
				slew-rate = "very-high-speed";
			};

			quadspi_bk2_io3_pe10: quadspi_bk2_io3_pe10 {
				pinmux = <STM32_PINMUX('E', 10, AF10)>;
				slew-rate = "very-high-speed";
			};

			quadspi_bk1_io3_pf6: quadspi_bk1_io3_pf6 {
				pinmux = <STM32_PINMUX('F', 6, AF9)>;
				slew-rate = "very-high-speed";
			};

			quadspi_bk1_io2_pf7: quadspi_bk1_io2_pf7 {
				pinmux = <STM32_PINMUX('F', 7, AF9)>;
				slew-rate = "very-high-speed";
			};

			quadspi_bk1_io0_pf8: quadspi_bk1_io0_pf8 {
				pinmux = <STM32_PINMUX('F', 8, AF10)>;
				slew-rate = "very-high-speed";
			};

			quadspi_bk1_io1_pf9: quadspi_bk1_io1_pf9 {
				pinmux = <STM32_PINMUX('F', 9, AF10)>;
				slew-rate = "very-high-speed";
			};

			quadspi_clk_pf10: quadspi_clk_pf10 {
				pinmux = <STM32_PINMUX('F', 10, AF9)>;
				slew-rate = "very-high-speed";
			};

			quadspi_bk2_io3_pg7: quadspi_bk2_io3_pg7 {
				pinmux = <STM32_PINMUX('G', 7, AF11)>;
				slew-rate = "very-high-speed";
			};

			quadspi_clk_pg7: quadspi_clk_pg7 {
				pinmux = <STM32_PINMUX('G', 7, AF9)>;
				slew-rate = "very-high-speed";
			};

			quadspi_bk2_io2_pg9: quadspi_bk2_io2_pg9 {
				pinmux = <STM32_PINMUX('G', 9, AF9)>;
				slew-rate = "very-high-speed";
			};

			quadspi_bk2_io2_pg10: quadspi_bk2_io2_pg10 {
				pinmux = <STM32_PINMUX('G', 10, AF11)>;
				slew-rate = "very-high-speed";
			};

			quadspi_bk2_io3_pg14: quadspi_bk2_io3_pg14 {
				pinmux = <STM32_PINMUX('G', 14, AF9)>;
				slew-rate = "very-high-speed";
			};

			quadspi_bk2_io0_ph2: quadspi_bk2_io0_ph2 {
				pinmux = <STM32_PINMUX('H', 2, AF9)>;
				slew-rate = "very-high-speed";
			};

			quadspi_bk2_io1_ph3: quadspi_bk2_io1_ph3 {
				pinmux = <STM32_PINMUX('H', 3, AF9)>;
				slew-rate = "very-high-speed";
			};

			/* SDMMC */

			sdmmc1_cdir_pa15: sdmmc1_cdir_pa15 {
				pinmux = <STM32_PINMUX('A', 15, AF3)>;
				slew-rate = "very-high-speed";
			};

			sdmmc1_d5_pa15: sdmmc1_d5_pa15 {
				pinmux = <STM32_PINMUX('A', 15, AF11)>;
				slew-rate = "very-high-speed";
			};

			sdmmc1_ckin_pb8: sdmmc1_ckin_pb8 {
				pinmux = <STM32_PINMUX('B', 8, AF5)>;
				slew-rate = "very-high-speed";
			};

			sdmmc1_d4_pb8: sdmmc1_d4_pb8 {
				pinmux = <STM32_PINMUX('B', 8, AF12)>;
				slew-rate = "very-high-speed";
			};

			sdmmc1_cdir_pb9: sdmmc1_cdir_pb9 {
				pinmux = <STM32_PINMUX('B', 9, AF11)>;
				slew-rate = "very-high-speed";
			};

			sdmmc1_d5_pb9: sdmmc1_d5_pb9 {
				pinmux = <STM32_PINMUX('B', 9, AF12)>;
				slew-rate = "very-high-speed";
			};

			sdmmc1_d0dir_pc6: sdmmc1_d0dir_pc6 {
				pinmux = <STM32_PINMUX('C', 6, AF8)>;
				slew-rate = "very-high-speed";
			};

			sdmmc1_d6_pc6: sdmmc1_d6_pc6 {
				pinmux = <STM32_PINMUX('C', 6, AF12)>;
				slew-rate = "very-high-speed";
			};

			sdmmc1_d123dir_pc7: sdmmc1_d123dir_pc7 {
				pinmux = <STM32_PINMUX('C', 7, AF8)>;
				slew-rate = "very-high-speed";
			};

			sdmmc1_d7_pc7: sdmmc1_d7_pc7 {
				pinmux = <STM32_PINMUX('C', 7, AF12)>;
				slew-rate = "very-high-speed";
			};

			sdmmc1_d0_pc8: sdmmc1_d0_pc8 {
				pinmux = <STM32_PINMUX('C', 8, AF12)>;
				slew-rate = "very-high-speed";
			};

			sdmmc1_d1_pc9: sdmmc1_d1_pc9 {
				pinmux = <STM32_PINMUX('C', 9, AF12)>;
				slew-rate = "very-high-speed";
			};

			sdmmc1_d2_pc10: sdmmc1_d2_pc10 {
				pinmux = <STM32_PINMUX('C', 10, AF12)>;
				slew-rate = "very-high-speed";
			};

			sdmmc1_d3_pc11: sdmmc1_d3_pc11 {
				pinmux = <STM32_PINMUX('C', 11, AF12)>;
				slew-rate = "very-high-speed";
			};

			sdmmc1_ck_pc12: sdmmc1_ck_pc12 {
				pinmux = <STM32_PINMUX('C', 12, AF12)>;
				slew-rate = "very-high-speed";
			};

			sdmmc1_cmd_pd2: sdmmc1_cmd_pd2 {
				pinmux = <STM32_PINMUX('D', 2, AF12)>;
				slew-rate = "very-high-speed";
			};

			sdmmc1_d123dir_pd3: sdmmc1_d123dir_pd3 {
				pinmux = <STM32_PINMUX('D', 3, AF8)>;
				slew-rate = "very-high-speed";
			};

			sdmmc1_d7_pd3: sdmmc1_d7_pd3 {
				pinmux = <STM32_PINMUX('D', 3, AF11)>;
				slew-rate = "very-high-speed";
			};

			sdmmc1_ckin_pe4: sdmmc1_ckin_pe4 {
				pinmux = <STM32_PINMUX('E', 4, AF8)>;
				slew-rate = "very-high-speed";
			};

			sdmmc1_d4_pe4: sdmmc1_d4_pe4 {
				pinmux = <STM32_PINMUX('E', 4, AF11)>;
				slew-rate = "very-high-speed";
			};

			sdmmc1_d0dir_pe5: sdmmc1_d0dir_pe5 {
				pinmux = <STM32_PINMUX('E', 5, AF8)>;
				slew-rate = "very-high-speed";
			};

			sdmmc1_d6_pe5: sdmmc1_d6_pe5 {
				pinmux = <STM32_PINMUX('E', 5, AF11)>;
				slew-rate = "very-high-speed";
			};

			sdmmc1_d2_pe6: sdmmc1_d2_pe6 {
				pinmux = <STM32_PINMUX('E', 6, AF8)>;
				slew-rate = "very-high-speed";
			};

			sdmmc1_d0dir_pe12: sdmmc1_d0dir_pe12 {
				pinmux = <STM32_PINMUX('E', 12, AF8)>;
				slew-rate = "very-high-speed";
			};

			sdmmc1_d123dir_pe14: sdmmc1_d123dir_pe14 {
				pinmux = <STM32_PINMUX('E', 14, AF11)>;
				slew-rate = "very-high-speed";
			};

			sdmmc1_d0dir_pf2: sdmmc1_d0dir_pf2 {
				pinmux = <STM32_PINMUX('F', 2, AF11)>;
				slew-rate = "very-high-speed";
			};

			sdmmc2_cmd_pa0: sdmmc2_cmd_pa0 {
				pinmux = <STM32_PINMUX('A', 0, AF9)>;
				slew-rate = "very-high-speed";
			};

			sdmmc2_d0dir_pa2: sdmmc2_d0dir_pa2 {
				pinmux = <STM32_PINMUX('A', 2, AF10)>;
				slew-rate = "very-high-speed";
			};

			sdmmc2_ckin_pa8: sdmmc2_ckin_pa8 {
				pinmux = <STM32_PINMUX('A', 8, AF8)>;
				slew-rate = "very-high-speed";
			};

			sdmmc2_d4_pa8: sdmmc2_d4_pa8 {
				pinmux = <STM32_PINMUX('A', 8, AF9)>;
				slew-rate = "very-high-speed";
			};

			sdmmc2_cdir_pa9: sdmmc2_cdir_pa9 {
				pinmux = <STM32_PINMUX('A', 9, AF8)>;
				slew-rate = "very-high-speed";
			};

			sdmmc2_d5_pa9: sdmmc2_d5_pa9 {
				pinmux = <STM32_PINMUX('A', 9, AF10)>;
				slew-rate = "very-high-speed";
			};

			sdmmc2_cdir_pa15: sdmmc2_cdir_pa15 {
				pinmux = <STM32_PINMUX('A', 15, AF10)>;
				slew-rate = "very-high-speed";
			};

			sdmmc2_d5_pa15: sdmmc2_d5_pa15 {
				pinmux = <STM32_PINMUX('A', 15, AF9)>;
				slew-rate = "very-high-speed";
			};

			sdmmc2_d2_pb3: sdmmc2_d2_pb3 {
				pinmux = <STM32_PINMUX('B', 3, AF9)>;
				slew-rate = "very-high-speed";
			};

			sdmmc2_d3_pb4: sdmmc2_d3_pb4 {
				pinmux = <STM32_PINMUX('B', 4, AF9)>;
				slew-rate = "very-high-speed";
			};

			sdmmc2_d1_pb7: sdmmc2_d1_pb7 {
				pinmux = <STM32_PINMUX('B', 7, AF10)>;
				slew-rate = "very-high-speed";
			};

			sdmmc2_ckin_pb8: sdmmc2_ckin_pb8 {
				pinmux = <STM32_PINMUX('B', 8, AF7)>;
				slew-rate = "very-high-speed";
			};

			sdmmc2_d4_pb8: sdmmc2_d4_pb8 {
				pinmux = <STM32_PINMUX('B', 8, AF10)>;
				slew-rate = "very-high-speed";
			};

			sdmmc2_cdir_pb9: sdmmc2_cdir_pb9 {
				pinmux = <STM32_PINMUX('B', 9, AF7)>;
				slew-rate = "very-high-speed";
			};

			sdmmc2_d5_pb9: sdmmc2_d5_pb9 {
				pinmux = <STM32_PINMUX('B', 9, AF10)>;
				slew-rate = "very-high-speed";
			};

			sdmmc2_d0_pb14: sdmmc2_d0_pb14 {
				pinmux = <STM32_PINMUX('B', 14, AF9)>;
				slew-rate = "very-high-speed";
			};

			sdmmc2_d1_pb15: sdmmc2_d1_pb15 {
				pinmux = <STM32_PINMUX('B', 15, AF9)>;
				slew-rate = "very-high-speed";
			};

			sdmmc2_ck_pc1: sdmmc2_ck_pc1 {
				pinmux = <STM32_PINMUX('C', 1, AF9)>;
				slew-rate = "very-high-speed";
			};

			sdmmc2_d0dir_pc6: sdmmc2_d0dir_pc6 {
				pinmux = <STM32_PINMUX('C', 6, AF9)>;
				slew-rate = "very-high-speed";
			};

			sdmmc2_d6_pc6: sdmmc2_d6_pc6 {
				pinmux = <STM32_PINMUX('C', 6, AF10)>;
				slew-rate = "very-high-speed";
			};

			sdmmc2_d123dir_pc7: sdmmc2_d123dir_pc7 {
				pinmux = <STM32_PINMUX('C', 7, AF9)>;
				slew-rate = "very-high-speed";
			};

			sdmmc2_d7_pc7: sdmmc2_d7_pc7 {
				pinmux = <STM32_PINMUX('C', 7, AF10)>;
				slew-rate = "very-high-speed";
			};

			sdmmc2_d123dir_pd3: sdmmc2_d123dir_pd3 {
				pinmux = <STM32_PINMUX('D', 3, AF10)>;
				slew-rate = "very-high-speed";
			};

			sdmmc2_d7_pd3: sdmmc2_d7_pd3 {
				pinmux = <STM32_PINMUX('D', 3, AF9)>;
				slew-rate = "very-high-speed";
			};

			sdmmc2_ck_pe3: sdmmc2_ck_pe3 {
				pinmux = <STM32_PINMUX('E', 3, AF9)>;
				slew-rate = "very-high-speed";
			};

			sdmmc2_ckin_pe4: sdmmc2_ckin_pe4 {
				pinmux = <STM32_PINMUX('E', 4, AF7)>;
				slew-rate = "very-high-speed";
			};

			sdmmc2_d4_pe4: sdmmc2_d4_pe4 {
				pinmux = <STM32_PINMUX('E', 4, AF9)>;
				slew-rate = "very-high-speed";
			};

			sdmmc2_d0dir_pe5: sdmmc2_d0dir_pe5 {
				pinmux = <STM32_PINMUX('E', 5, AF7)>;
				slew-rate = "very-high-speed";
			};

			sdmmc2_d6_pe5: sdmmc2_d6_pe5 {
				pinmux = <STM32_PINMUX('E', 5, AF9)>;
				slew-rate = "very-high-speed";
			};

			sdmmc2_d0_pe6: sdmmc2_d0_pe6 {
				pinmux = <STM32_PINMUX('E', 6, AF7)>;
				slew-rate = "very-high-speed";
			};

			sdmmc2_d0dir_pf2: sdmmc2_d0dir_pf2 {
				pinmux = <STM32_PINMUX('F', 2, AF9)>;
				slew-rate = "very-high-speed";
			};

			sdmmc2_cmd_pg6: sdmmc2_cmd_pg6 {
				pinmux = <STM32_PINMUX('G', 6, AF10)>;
				slew-rate = "very-high-speed";
			};

			sdmmc3_cmd_pd0: sdmmc3_cmd_pd0 {
				pinmux = <STM32_PINMUX('D', 0, AF10)>;
				slew-rate = "very-high-speed";
			};

			sdmmc3_d0_pd1: sdmmc3_d0_pd1 {
				pinmux = <STM32_PINMUX('D', 1, AF10)>;
				slew-rate = "very-high-speed";
			};

			sdmmc3_d1_pd4: sdmmc3_d1_pd4 {
				pinmux = <STM32_PINMUX('D', 4, AF10)>;
				slew-rate = "very-high-speed";
			};

			sdmmc3_d2_pd5: sdmmc3_d2_pd5 {
				pinmux = <STM32_PINMUX('D', 5, AF10)>;
				slew-rate = "very-high-speed";
			};

			sdmmc3_d3_pd7: sdmmc3_d3_pd7 {
				pinmux = <STM32_PINMUX('D', 7, AF10)>;
				slew-rate = "very-high-speed";
			};

			sdmmc3_ckin_pf0: sdmmc3_ckin_pf0 {
				pinmux = <STM32_PINMUX('F', 0, AF10)>;
				slew-rate = "very-high-speed";
			};

			sdmmc3_d0_pf0: sdmmc3_d0_pf0 {
				pinmux = <STM32_PINMUX('F', 0, AF9)>;
				slew-rate = "very-high-speed";
			};

			sdmmc3_cdir_pf1: sdmmc3_cdir_pf1 {
				pinmux = <STM32_PINMUX('F', 1, AF10)>;
				slew-rate = "very-high-speed";
			};

			sdmmc3_cmd_pf1: sdmmc3_cmd_pf1 {
				pinmux = <STM32_PINMUX('F', 1, AF9)>;
				slew-rate = "very-high-speed";
			};

			sdmmc3_d0dir_pf2: sdmmc3_d0dir_pf2 {
				pinmux = <STM32_PINMUX('F', 2, AF10)>;
				slew-rate = "very-high-speed";
			};

			sdmmc3_d1_pf4: sdmmc3_d1_pf4 {
				pinmux = <STM32_PINMUX('F', 4, AF9)>;
				slew-rate = "very-high-speed";
			};

			sdmmc3_d123dir_pf4: sdmmc3_d123dir_pf4 {
				pinmux = <STM32_PINMUX('F', 4, AF10)>;
				slew-rate = "very-high-speed";
			};

			sdmmc3_d2_pf5: sdmmc3_d2_pf5 {
				pinmux = <STM32_PINMUX('F', 5, AF9)>;
				slew-rate = "very-high-speed";
			};

			sdmmc3_ck_pg15: sdmmc3_ck_pg15 {
				pinmux = <STM32_PINMUX('G', 15, AF10)>;
				slew-rate = "very-high-speed";
			};

			/* SPI_MISO */

			spi1_miso_pa6: spi1_miso_pa6 {
				pinmux = <STM32_PINMUX('A', 6, AF5)>;
				bias-pull-down;
			};

			spi1_miso_pb4: spi1_miso_pb4 {
				pinmux = <STM32_PINMUX('B', 4, AF5)>;
				bias-pull-down;
			};

			spi1_miso_pz1: spi1_miso_pz1 {
				pinmux = <STM32_PINMUX('Z', 1, AF5)>;
				bias-pull-down;
			};

			spi2_miso_pb14: spi2_miso_pb14 {
				pinmux = <STM32_PINMUX('B', 14, AF5)>;
				bias-pull-down;
			};

			spi2_miso_pc2: spi2_miso_pc2 {
				pinmux = <STM32_PINMUX('C', 2, AF5)>;
				bias-pull-down;
			};

			spi2_miso_pi2: spi2_miso_pi2 {
				pinmux = <STM32_PINMUX('I', 2, AF5)>;
				bias-pull-down;
			};

			spi3_miso_pb4: spi3_miso_pb4 {
				pinmux = <STM32_PINMUX('B', 4, AF6)>;
				bias-pull-down;
			};

			spi3_miso_pc11: spi3_miso_pc11 {
				pinmux = <STM32_PINMUX('C', 11, AF6)>;
				bias-pull-down;
			};

			spi3_miso_pd10: spi3_miso_pd10 {
				pinmux = <STM32_PINMUX('D', 10, AF5)>;
				bias-pull-down;
			};

			spi4_miso_pe5: spi4_miso_pe5 {
				pinmux = <STM32_PINMUX('E', 5, AF5)>;
				bias-pull-down;
			};

			spi4_miso_pe13: spi4_miso_pe13 {
				pinmux = <STM32_PINMUX('E', 13, AF5)>;
				bias-pull-down;
			};

			spi5_miso_pf8: spi5_miso_pf8 {
				pinmux = <STM32_PINMUX('F', 8, AF5)>;
				bias-pull-down;
			};

			spi5_miso_ph7: spi5_miso_ph7 {
				pinmux = <STM32_PINMUX('H', 7, AF5)>;
				bias-pull-down;
			};

			spi6_miso_pa6: spi6_miso_pa6 {
				pinmux = <STM32_PINMUX('A', 6, AF8)>;
				bias-pull-down;
			};

			spi6_miso_pb4: spi6_miso_pb4 {
				pinmux = <STM32_PINMUX('B', 4, AF8)>;
				bias-pull-down;
			};

			spi6_miso_pg12: spi6_miso_pg12 {
				pinmux = <STM32_PINMUX('G', 12, AF5)>;
				bias-pull-down;
			};

			spi6_miso_pz1: spi6_miso_pz1 {
				pinmux = <STM32_PINMUX('Z', 1, AF8)>;
				bias-pull-down;
			};

			/* SPI_MOSI */

			spi1_mosi_pa7: spi1_mosi_pa7 {
				pinmux = <STM32_PINMUX('A', 7, AF5)>;
				bias-pull-down;
			};

			spi1_mosi_pb5: spi1_mosi_pb5 {
				pinmux = <STM32_PINMUX('B', 5, AF5)>;
				bias-pull-down;
			};

			spi1_mosi_pz2: spi1_mosi_pz2 {
				pinmux = <STM32_PINMUX('Z', 2, AF5)>;
				bias-pull-down;
			};

			spi2_mosi_pb15: spi2_mosi_pb15 {
				pinmux = <STM32_PINMUX('B', 15, AF5)>;
				bias-pull-down;
			};

			spi2_mosi_pc1: spi2_mosi_pc1 {
				pinmux = <STM32_PINMUX('C', 1, AF5)>;
				bias-pull-down;
			};

			spi2_mosi_pc3: spi2_mosi_pc3 {
				pinmux = <STM32_PINMUX('C', 3, AF5)>;
				bias-pull-down;
			};

			spi2_mosi_pi3: spi2_mosi_pi3 {
				pinmux = <STM32_PINMUX('I', 3, AF5)>;
				bias-pull-down;
			};

			spi3_mosi_pa8: spi3_mosi_pa8 {
				pinmux = <STM32_PINMUX('A', 8, AF5)>;
				bias-pull-down;
			};

			spi3_mosi_pb2: spi3_mosi_pb2 {
				pinmux = <STM32_PINMUX('B', 2, AF7)>;
				bias-pull-down;
			};

			spi3_mosi_pb5: spi3_mosi_pb5 {
				pinmux = <STM32_PINMUX('B', 5, AF7)>;
				bias-pull-down;
			};

			spi3_mosi_pc12: spi3_mosi_pc12 {
				pinmux = <STM32_PINMUX('C', 12, AF6)>;
				bias-pull-down;
			};

			spi3_mosi_pd6: spi3_mosi_pd6 {
				pinmux = <STM32_PINMUX('D', 6, AF5)>;
				bias-pull-down;
			};

			spi4_mosi_pe6: spi4_mosi_pe6 {
				pinmux = <STM32_PINMUX('E', 6, AF5)>;
				bias-pull-down;
			};

			spi4_mosi_pe14: spi4_mosi_pe14 {
				pinmux = <STM32_PINMUX('E', 14, AF5)>;
				bias-pull-down;
			};

			spi5_mosi_pf9: spi5_mosi_pf9 {
				pinmux = <STM32_PINMUX('F', 9, AF5)>;
				bias-pull-down;
			};

			spi5_mosi_pf11: spi5_mosi_pf11 {
				pinmux = <STM32_PINMUX('F', 11, AF5)>;
				bias-pull-down;
			};

			spi6_mosi_pa7: spi6_mosi_pa7 {
				pinmux = <STM32_PINMUX('A', 7, AF8)>;
				bias-pull-down;
			};

			spi6_mosi_pb5: spi6_mosi_pb5 {
				pinmux = <STM32_PINMUX('B', 5, AF8)>;
				bias-pull-down;
			};

			spi6_mosi_pg14: spi6_mosi_pg14 {
				pinmux = <STM32_PINMUX('G', 14, AF5)>;
				bias-pull-down;
			};

			spi6_mosi_pz2: spi6_mosi_pz2 {
				pinmux = <STM32_PINMUX('Z', 2, AF8)>;
				bias-pull-down;
			};

			/* SPI_NSS */

			spi1_nss_pa4: spi1_nss_pa4 {
				pinmux = <STM32_PINMUX('A', 4, AF5)>;
				bias-pull-up;
			};

			spi1_nss_pa15: spi1_nss_pa15 {
				pinmux = <STM32_PINMUX('A', 15, AF5)>;
				bias-pull-up;
			};

			spi1_nss_pz3: spi1_nss_pz3 {
				pinmux = <STM32_PINMUX('Z', 3, AF5)>;
				bias-pull-up;
			};

			spi2_nss_pa11: spi2_nss_pa11 {
				pinmux = <STM32_PINMUX('A', 11, AF5)>;
				bias-pull-up;
			};

			spi2_nss_pb4: spi2_nss_pb4 {
				pinmux = <STM32_PINMUX('B', 4, AF7)>;
				bias-pull-up;
			};

			spi2_nss_pb9: spi2_nss_pb9 {
				pinmux = <STM32_PINMUX('B', 9, AF5)>;
				bias-pull-up;
			};

			spi2_nss_pb12: spi2_nss_pb12 {
				pinmux = <STM32_PINMUX('B', 12, AF5)>;
				bias-pull-up;
			};

			spi2_nss_pi0: spi2_nss_pi0 {
				pinmux = <STM32_PINMUX('I', 0, AF5)>;
				bias-pull-up;
			};

			spi3_nss_pa4: spi3_nss_pa4 {
				pinmux = <STM32_PINMUX('A', 4, AF6)>;
				bias-pull-up;
			};

			spi3_nss_pa10: spi3_nss_pa10 {
				pinmux = <STM32_PINMUX('A', 10, AF5)>;
				bias-pull-up;
			};

			spi3_nss_pa15: spi3_nss_pa15 {
				pinmux = <STM32_PINMUX('A', 15, AF6)>;
				bias-pull-up;
			};

			spi4_nss_pe4: spi4_nss_pe4 {
				pinmux = <STM32_PINMUX('E', 4, AF5)>;
				bias-pull-up;
			};

			spi4_nss_pe11: spi4_nss_pe11 {
				pinmux = <STM32_PINMUX('E', 11, AF5)>;
				bias-pull-up;
			};

			spi5_nss_pf6: spi5_nss_pf6 {
				pinmux = <STM32_PINMUX('F', 6, AF5)>;
				bias-pull-up;
			};

			spi5_nss_ph5: spi5_nss_ph5 {
				pinmux = <STM32_PINMUX('H', 5, AF5)>;
				bias-pull-up;
			};

			spi6_nss_pa4: spi6_nss_pa4 {
				pinmux = <STM32_PINMUX('A', 4, AF8)>;
				bias-pull-up;
			};

			spi6_nss_pa15: spi6_nss_pa15 {
				pinmux = <STM32_PINMUX('A', 15, AF7)>;
				bias-pull-up;
			};

			spi6_nss_pg8: spi6_nss_pg8 {
				pinmux = <STM32_PINMUX('G', 8, AF5)>;
				bias-pull-up;
			};

			spi6_nss_pz3: spi6_nss_pz3 {
				pinmux = <STM32_PINMUX('Z', 3, AF8)>;
				bias-pull-up;
			};

			/* SPI_SCK */

			spi1_sck_pa5: spi1_sck_pa5 {
				pinmux = <STM32_PINMUX('A', 5, AF5)>;
				slew-rate = "very-high-speed";
			};

			spi1_sck_pb3: spi1_sck_pb3 {
				pinmux = <STM32_PINMUX('B', 3, AF5)>;
				slew-rate = "very-high-speed";
			};

			spi1_sck_pz0: spi1_sck_pz0 {
				pinmux = <STM32_PINMUX('Z', 0, AF5)>;
				slew-rate = "very-high-speed";
			};

			spi2_sck_pa9: spi2_sck_pa9 {
				pinmux = <STM32_PINMUX('A', 9, AF5)>;
				slew-rate = "very-high-speed";
			};

			spi2_sck_pb10: spi2_sck_pb10 {
				pinmux = <STM32_PINMUX('B', 10, AF5)>;
				slew-rate = "very-high-speed";
			};

			spi2_sck_pb13: spi2_sck_pb13 {
				pinmux = <STM32_PINMUX('B', 13, AF5)>;
				slew-rate = "very-high-speed";
			};

			spi2_sck_pd3: spi2_sck_pd3 {
				pinmux = <STM32_PINMUX('D', 3, AF5)>;
				slew-rate = "very-high-speed";
			};

			spi2_sck_pi1: spi2_sck_pi1 {
				pinmux = <STM32_PINMUX('I', 1, AF5)>;
				slew-rate = "very-high-speed";
			};

			spi3_sck_pb3: spi3_sck_pb3 {
				pinmux = <STM32_PINMUX('B', 3, AF6)>;
				slew-rate = "very-high-speed";
			};

			spi3_sck_pc10: spi3_sck_pc10 {
				pinmux = <STM32_PINMUX('C', 10, AF6)>;
				slew-rate = "very-high-speed";
			};

			spi3_sck_pe0: spi3_sck_pe0 {
				pinmux = <STM32_PINMUX('E', 0, AF5)>;
				slew-rate = "very-high-speed";
			};

			spi4_sck_pe2: spi4_sck_pe2 {
				pinmux = <STM32_PINMUX('E', 2, AF5)>;
				slew-rate = "very-high-speed";
			};

			spi4_sck_pe12: spi4_sck_pe12 {
				pinmux = <STM32_PINMUX('E', 12, AF5)>;
				slew-rate = "very-high-speed";
			};

			spi5_sck_pf7: spi5_sck_pf7 {
				pinmux = <STM32_PINMUX('F', 7, AF5)>;
				slew-rate = "very-high-speed";
			};

			spi5_sck_ph6: spi5_sck_ph6 {
				pinmux = <STM32_PINMUX('H', 6, AF5)>;
				slew-rate = "very-high-speed";
			};

			spi6_sck_pa5: spi6_sck_pa5 {
				pinmux = <STM32_PINMUX('A', 5, AF8)>;
				slew-rate = "very-high-speed";
			};

			spi6_sck_pb3: spi6_sck_pb3 {
				pinmux = <STM32_PINMUX('B', 3, AF8)>;
				slew-rate = "very-high-speed";
			};

			spi6_sck_pg13: spi6_sck_pg13 {
				pinmux = <STM32_PINMUX('G', 13, AF5)>;
				slew-rate = "very-high-speed";
			};

			spi6_sck_pz0: spi6_sck_pz0 {
				pinmux = <STM32_PINMUX('Z', 0, AF8)>;
				slew-rate = "very-high-speed";
			};

			/* TIM_CH / TIM_CHN */

			tim1_ch1n_pa7: tim1_ch1n_pa7 {
				pinmux = <STM32_PINMUX('A', 7, AF1)>;
			};

			tim1_ch1_pa8: tim1_ch1_pa8 {
				pinmux = <STM32_PINMUX('A', 8, AF1)>;
			};

			tim1_ch2_pa9: tim1_ch2_pa9 {
				pinmux = <STM32_PINMUX('A', 9, AF1)>;
			};

			tim1_ch3_pa10: tim1_ch3_pa10 {
				pinmux = <STM32_PINMUX('A', 10, AF1)>;
			};

			tim1_ch4_pa11: tim1_ch4_pa11 {
				pinmux = <STM32_PINMUX('A', 11, AF1)>;
			};

			tim1_ch2n_pb0: tim1_ch2n_pb0 {
				pinmux = <STM32_PINMUX('B', 0, AF1)>;
			};

			tim1_ch3n_pb1: tim1_ch3n_pb1 {
				pinmux = <STM32_PINMUX('B', 1, AF1)>;
			};

			tim1_ch1n_pb13: tim1_ch1n_pb13 {
				pinmux = <STM32_PINMUX('B', 13, AF1)>;
			};

			tim1_ch2n_pb14: tim1_ch2n_pb14 {
				pinmux = <STM32_PINMUX('B', 14, AF1)>;
			};

			tim1_ch3n_pb15: tim1_ch3n_pb15 {
				pinmux = <STM32_PINMUX('B', 15, AF1)>;
			};

			tim1_ch1n_pe8: tim1_ch1n_pe8 {
				pinmux = <STM32_PINMUX('E', 8, AF1)>;
			};

			tim1_ch1_pe9: tim1_ch1_pe9 {
				pinmux = <STM32_PINMUX('E', 9, AF1)>;
			};

			tim1_ch2n_pe10: tim1_ch2n_pe10 {
				pinmux = <STM32_PINMUX('E', 10, AF1)>;
			};

			tim1_ch2_pe11: tim1_ch2_pe11 {
				pinmux = <STM32_PINMUX('E', 11, AF1)>;
			};

			tim1_ch3n_pe12: tim1_ch3n_pe12 {
				pinmux = <STM32_PINMUX('E', 12, AF1)>;
			};

			tim1_ch3_pe13: tim1_ch3_pe13 {
				pinmux = <STM32_PINMUX('E', 13, AF1)>;
			};

			tim1_ch4_pe14: tim1_ch4_pe14 {
				pinmux = <STM32_PINMUX('E', 14, AF1)>;
			};

			tim2_ch1_pa0: tim2_ch1_pa0 {
				pinmux = <STM32_PINMUX('A', 0, AF1)>;
			};

			tim2_ch2_pa1: tim2_ch2_pa1 {
				pinmux = <STM32_PINMUX('A', 1, AF1)>;
			};

			tim2_ch3_pa2: tim2_ch3_pa2 {
				pinmux = <STM32_PINMUX('A', 2, AF1)>;
			};

			tim2_ch4_pa3: tim2_ch4_pa3 {
				pinmux = <STM32_PINMUX('A', 3, AF1)>;
			};

			tim2_ch1_pa5: tim2_ch1_pa5 {
				pinmux = <STM32_PINMUX('A', 5, AF1)>;
			};

			tim2_ch1_pa15: tim2_ch1_pa15 {
				pinmux = <STM32_PINMUX('A', 15, AF1)>;
			};

			tim2_ch2_pb3: tim2_ch2_pb3 {
				pinmux = <STM32_PINMUX('B', 3, AF1)>;
			};

			tim2_ch3_pb10: tim2_ch3_pb10 {
				pinmux = <STM32_PINMUX('B', 10, AF1)>;
			};

			tim2_ch4_pb11: tim2_ch4_pb11 {
				pinmux = <STM32_PINMUX('B', 11, AF1)>;
			};

			tim12_ch1_pb14: tim12_ch1_pb14 {
				pinmux = <STM32_PINMUX('B', 14, AF2)>;
			};

			tim12_ch2_pb15: tim12_ch2_pb15 {
				pinmux = <STM32_PINMUX('B', 15, AF2)>;
			};

			tim2_ch1_pg8: tim2_ch1_pg8 {
				pinmux = <STM32_PINMUX('G', 8, AF1)>;
			};

			tim12_ch1_ph6: tim12_ch1_ph6 {
				pinmux = <STM32_PINMUX('H', 6, AF2)>;
			};

			tim12_ch2_ph9: tim12_ch2_ph9 {
				pinmux = <STM32_PINMUX('H', 9, AF2)>;
			};

			tim13_ch1_pa6: tim13_ch1_pa6 {
				pinmux = <STM32_PINMUX('A', 6, AF9)>;
			};

			tim3_ch1_pa6: tim3_ch1_pa6 {
				pinmux = <STM32_PINMUX('A', 6, AF2)>;
			};

			tim3_ch2_pa7: tim3_ch2_pa7 {
				pinmux = <STM32_PINMUX('A', 7, AF2)>;
			};

			tim3_ch3_pb0: tim3_ch3_pb0 {
				pinmux = <STM32_PINMUX('B', 0, AF2)>;
			};

			tim3_ch4_pb1: tim3_ch4_pb1 {
				pinmux = <STM32_PINMUX('B', 1, AF2)>;
			};

			tim3_ch1_pb4: tim3_ch1_pb4 {
				pinmux = <STM32_PINMUX('B', 4, AF2)>;
			};

			tim3_ch2_pb5: tim3_ch2_pb5 {
				pinmux = <STM32_PINMUX('B', 5, AF2)>;
			};

			tim3_ch1_pc6: tim3_ch1_pc6 {
				pinmux = <STM32_PINMUX('C', 6, AF2)>;
			};

			tim3_ch2_pc7: tim3_ch2_pc7 {
				pinmux = <STM32_PINMUX('C', 7, AF2)>;
			};

			tim3_ch3_pc8: tim3_ch3_pc8 {
				pinmux = <STM32_PINMUX('C', 8, AF2)>;
			};

			tim3_ch4_pc9: tim3_ch4_pc9 {
				pinmux = <STM32_PINMUX('C', 9, AF2)>;
			};

			tim13_ch1_pf8: tim13_ch1_pf8 {
				pinmux = <STM32_PINMUX('F', 8, AF9)>;
			};

			tim14_ch1_pa7: tim14_ch1_pa7 {
				pinmux = <STM32_PINMUX('A', 7, AF9)>;
			};

			tim4_ch1_pb6: tim4_ch1_pb6 {
				pinmux = <STM32_PINMUX('B', 6, AF2)>;
			};

			tim4_ch2_pb7: tim4_ch2_pb7 {
				pinmux = <STM32_PINMUX('B', 7, AF2)>;
			};

			tim4_ch3_pb8: tim4_ch3_pb8 {
				pinmux = <STM32_PINMUX('B', 8, AF2)>;
			};

			tim4_ch4_pb9: tim4_ch4_pb9 {
				pinmux = <STM32_PINMUX('B', 9, AF2)>;
			};

			tim4_ch1_pd12: tim4_ch1_pd12 {
				pinmux = <STM32_PINMUX('D', 12, AF2)>;
			};

			tim4_ch2_pd13: tim4_ch2_pd13 {
				pinmux = <STM32_PINMUX('D', 13, AF2)>;
			};

			tim4_ch3_pd14: tim4_ch3_pd14 {
				pinmux = <STM32_PINMUX('D', 14, AF2)>;
			};

			tim4_ch4_pd15: tim4_ch4_pd15 {
				pinmux = <STM32_PINMUX('D', 15, AF2)>;
			};

			tim14_ch1_pf9: tim14_ch1_pf9 {
				pinmux = <STM32_PINMUX('F', 9, AF9)>;
			};

			tim5_ch1_pa0: tim5_ch1_pa0 {
				pinmux = <STM32_PINMUX('A', 0, AF2)>;
			};

			tim15_ch1n_pa1: tim15_ch1n_pa1 {
				pinmux = <STM32_PINMUX('A', 1, AF4)>;
			};

			tim5_ch2_pa1: tim5_ch2_pa1 {
				pinmux = <STM32_PINMUX('A', 1, AF2)>;
			};

			tim15_ch1_pa2: tim15_ch1_pa2 {
				pinmux = <STM32_PINMUX('A', 2, AF4)>;
			};

			tim5_ch3_pa2: tim5_ch3_pa2 {
				pinmux = <STM32_PINMUX('A', 2, AF2)>;
			};

			tim15_ch2_pa3: tim15_ch2_pa3 {
				pinmux = <STM32_PINMUX('A', 3, AF4)>;
			};

			tim5_ch4_pa3: tim5_ch4_pa3 {
				pinmux = <STM32_PINMUX('A', 3, AF2)>;
			};

			tim15_ch1n_pe4: tim15_ch1n_pe4 {
				pinmux = <STM32_PINMUX('E', 4, AF4)>;
			};

			tim15_ch1_pe5: tim15_ch1_pe5 {
				pinmux = <STM32_PINMUX('E', 5, AF4)>;
			};

			tim15_ch2_pe6: tim15_ch2_pe6 {
				pinmux = <STM32_PINMUX('E', 6, AF4)>;
			};

			tim5_ch1_ph10: tim5_ch1_ph10 {
				pinmux = <STM32_PINMUX('H', 10, AF2)>;
			};

			tim5_ch2_ph11: tim5_ch2_ph11 {
				pinmux = <STM32_PINMUX('H', 11, AF2)>;
			};

			tim5_ch3_ph12: tim5_ch3_ph12 {
				pinmux = <STM32_PINMUX('H', 12, AF2)>;
			};

			tim5_ch4_pi0: tim5_ch4_pi0 {
				pinmux = <STM32_PINMUX('I', 0, AF2)>;
			};

			tim16_ch1n_pb6: tim16_ch1n_pb6 {
				pinmux = <STM32_PINMUX('B', 6, AF1)>;
			};

			tim16_ch1_pb8: tim16_ch1_pb8 {
				pinmux = <STM32_PINMUX('B', 8, AF1)>;
			};

			tim16_ch1n_pd6: tim16_ch1n_pd6 {
				pinmux = <STM32_PINMUX('D', 6, AF1)>;
			};

			tim16_ch1_pf6: tim16_ch1_pf6 {
				pinmux = <STM32_PINMUX('F', 6, AF1)>;
			};

			tim16_ch1n_pf8: tim16_ch1n_pf8 {
				pinmux = <STM32_PINMUX('F', 8, AF1)>;
			};

			tim17_ch1n_pb7: tim17_ch1n_pb7 {
				pinmux = <STM32_PINMUX('B', 7, AF1)>;
			};

			tim17_ch1_pb9: tim17_ch1_pb9 {
				pinmux = <STM32_PINMUX('B', 9, AF1)>;
			};

			tim17_ch1_pf7: tim17_ch1_pf7 {
				pinmux = <STM32_PINMUX('F', 7, AF1)>;
			};

			tim17_ch1n_pf9: tim17_ch1n_pf9 {
				pinmux = <STM32_PINMUX('F', 9, AF1)>;
			};

			tim8_ch1n_pa5: tim8_ch1n_pa5 {
				pinmux = <STM32_PINMUX('A', 5, AF3)>;
			};

			tim8_ch1n_pa7: tim8_ch1n_pa7 {
				pinmux = <STM32_PINMUX('A', 7, AF3)>;
			};

			tim8_ch2n_pb0: tim8_ch2n_pb0 {
				pinmux = <STM32_PINMUX('B', 0, AF3)>;
			};

			tim8_ch3n_pb1: tim8_ch3n_pb1 {
				pinmux = <STM32_PINMUX('B', 1, AF3)>;
			};

			tim8_ch2n_pb14: tim8_ch2n_pb14 {
				pinmux = <STM32_PINMUX('B', 14, AF3)>;
			};

			tim8_ch3n_pb15: tim8_ch3n_pb15 {
				pinmux = <STM32_PINMUX('B', 15, AF3)>;
			};

			tim8_ch1_pc6: tim8_ch1_pc6 {
				pinmux = <STM32_PINMUX('C', 6, AF3)>;
			};

			tim8_ch2_pc7: tim8_ch2_pc7 {
				pinmux = <STM32_PINMUX('C', 7, AF3)>;
			};

			tim8_ch3_pc8: tim8_ch3_pc8 {
				pinmux = <STM32_PINMUX('C', 8, AF3)>;
			};

			tim8_ch4_pc9: tim8_ch4_pc9 {
				pinmux = <STM32_PINMUX('C', 9, AF3)>;
			};

			tim8_ch1n_ph13: tim8_ch1n_ph13 {
				pinmux = <STM32_PINMUX('H', 13, AF3)>;
			};

			tim8_ch2n_ph14: tim8_ch2n_ph14 {
				pinmux = <STM32_PINMUX('H', 14, AF3)>;
			};

			tim8_ch3n_ph15: tim8_ch3n_ph15 {
				pinmux = <STM32_PINMUX('H', 15, AF3)>;
			};

			tim8_ch4_pi2: tim8_ch4_pi2 {
				pinmux = <STM32_PINMUX('I', 2, AF3)>;
			};

			tim8_ch1_pi5: tim8_ch1_pi5 {
				pinmux = <STM32_PINMUX('I', 5, AF3)>;
			};

			tim8_ch2_pi6: tim8_ch2_pi6 {
				pinmux = <STM32_PINMUX('I', 6, AF3)>;
			};

			tim8_ch3_pi7: tim8_ch3_pi7 {
				pinmux = <STM32_PINMUX('I', 7, AF3)>;
			};

			/* UART_CTS / USART_CTS / LPUART_CTS */

			usart1_cts_pa11: usart1_cts_pa11 {
				pinmux = <STM32_PINMUX('A', 11, AF7)>;
				bias-pull-up;
				drive-open-drain;
			};

			usart1_cts_pz3: usart1_cts_pz3 {
				pinmux = <STM32_PINMUX('Z', 3, AF7)>;
				bias-pull-up;
				drive-open-drain;
			};

			usart2_cts_pa0: usart2_cts_pa0 {
				pinmux = <STM32_PINMUX('A', 0, AF7)>;
				bias-pull-up;
				drive-open-drain;
			};

			usart2_cts_pd3: usart2_cts_pd3 {
				pinmux = <STM32_PINMUX('D', 3, AF7)>;
				bias-pull-up;
				drive-open-drain;
			};

			usart2_cts_pe15: usart2_cts_pe15 {
				pinmux = <STM32_PINMUX('E', 15, AF7)>;
				bias-pull-up;
				drive-open-drain;
			};

			usart3_cts_pb13: usart3_cts_pb13 {
				pinmux = <STM32_PINMUX('B', 13, AF7)>;
				bias-pull-up;
				drive-open-drain;
			};

			usart3_cts_pd11: usart3_cts_pd11 {
				pinmux = <STM32_PINMUX('D', 11, AF7)>;
				bias-pull-up;
				drive-open-drain;
			};

			usart3_cts_pi10: usart3_cts_pi10 {
				pinmux = <STM32_PINMUX('I', 10, AF8)>;
				bias-pull-up;
				drive-open-drain;
			};

			uart4_cts_pb0: uart4_cts_pb0 {
				pinmux = <STM32_PINMUX('B', 0, AF8)>;
				bias-pull-up;
				drive-open-drain;
			};

			uart5_cts_pc9: uart5_cts_pc9 {
				pinmux = <STM32_PINMUX('C', 9, AF8)>;
				bias-pull-up;
				drive-open-drain;
			};

			usart6_cts_pg13: usart6_cts_pg13 {
				pinmux = <STM32_PINMUX('G', 13, AF7)>;
				bias-pull-up;
				drive-open-drain;
			};

			usart6_cts_pg15: usart6_cts_pg15 {
				pinmux = <STM32_PINMUX('G', 15, AF7)>;
				bias-pull-up;
				drive-open-drain;
			};

			uart7_cts_pe10: uart7_cts_pe10 {
				pinmux = <STM32_PINMUX('E', 10, AF7)>;
				bias-pull-up;
				drive-open-drain;
			};

			uart7_cts_pf9: uart7_cts_pf9 {
				pinmux = <STM32_PINMUX('F', 9, AF7)>;
				bias-pull-up;
				drive-open-drain;
			};

			uart8_cts_pd14: uart8_cts_pd14 {
				pinmux = <STM32_PINMUX('D', 14, AF8)>;
				bias-pull-up;
				drive-open-drain;
			};

			uart8_cts_pd15: uart8_cts_pd15 {
				pinmux = <STM32_PINMUX('D', 15, AF8)>;
				bias-pull-up;
				drive-open-drain;
			};

			uart8_cts_pe15: uart8_cts_pe15 {
				pinmux = <STM32_PINMUX('E', 15, AF8)>;
				bias-pull-up;
				drive-open-drain;
			};

			uart8_cts_pg10: uart8_cts_pg10 {
				pinmux = <STM32_PINMUX('G', 10, AF8)>;
				bias-pull-up;
				drive-open-drain;
			};

			/* UART_RTS / USART_RTS / LPUART_RTS */

			usart1_rts_pa12: usart1_rts_pa12 {
				pinmux = <STM32_PINMUX('A', 12, AF7)>;
				bias-pull-up;
				drive-open-drain;
			};

			usart1_rts_pz5: usart1_rts_pz5 {
				pinmux = <STM32_PINMUX('Z', 5, AF7)>;
				bias-pull-up;
				drive-open-drain;
			};

			usart2_rts_pa1: usart2_rts_pa1 {
				pinmux = <STM32_PINMUX('A', 1, AF7)>;
				bias-pull-up;
				drive-open-drain;
			};

			usart2_rts_pd4: usart2_rts_pd4 {
				pinmux = <STM32_PINMUX('D', 4, AF7)>;
				bias-pull-up;
				drive-open-drain;
			};

			usart3_rts_pb14: usart3_rts_pb14 {
				pinmux = <STM32_PINMUX('B', 14, AF7)>;
				bias-pull-up;
				drive-open-drain;
			};

			usart3_rts_pd12: usart3_rts_pd12 {
				pinmux = <STM32_PINMUX('D', 12, AF7)>;
				bias-pull-up;
				drive-open-drain;
			};

			usart3_rts_pg8: usart3_rts_pg8 {
				pinmux = <STM32_PINMUX('G', 8, AF8)>;
				bias-pull-up;
				drive-open-drain;
			};

			uart4_rts_pa15: uart4_rts_pa15 {
				pinmux = <STM32_PINMUX('A', 15, AF8)>;
				bias-pull-up;
				drive-open-drain;
			};

			uart5_rts_pc8: uart5_rts_pc8 {
				pinmux = <STM32_PINMUX('C', 8, AF8)>;
				bias-pull-up;
				drive-open-drain;
			};

			usart6_rts_pg8: usart6_rts_pg8 {
				pinmux = <STM32_PINMUX('G', 8, AF7)>;
				bias-pull-up;
				drive-open-drain;
			};

			usart6_rts_pg12: usart6_rts_pg12 {
				pinmux = <STM32_PINMUX('G', 12, AF7)>;
				bias-pull-up;
				drive-open-drain;
			};

			uart7_rts_pe9: uart7_rts_pe9 {
				pinmux = <STM32_PINMUX('E', 9, AF7)>;
				bias-pull-up;
				drive-open-drain;
			};

			uart7_rts_pf8: uart7_rts_pf8 {
				pinmux = <STM32_PINMUX('F', 8, AF7)>;
				bias-pull-up;
				drive-open-drain;
			};

			uart8_rts_pe14: uart8_rts_pe14 {
				pinmux = <STM32_PINMUX('E', 14, AF8)>;
				bias-pull-up;
				drive-open-drain;
			};

			uart8_rts_pg7: uart8_rts_pg7 {
				pinmux = <STM32_PINMUX('G', 7, AF8)>;
				bias-pull-up;
				drive-open-drain;
			};

			/* UART_RX / USART_RX / LPUART_RX */

			usart1_rx_pa10: usart1_rx_pa10 {
				pinmux = <STM32_PINMUX('A', 10, AF7)>;
			};

			usart1_rx_pb2: usart1_rx_pb2 {
				pinmux = <STM32_PINMUX('B', 2, AF4)>;
			};

			usart1_rx_pb7: usart1_rx_pb7 {
				pinmux = <STM32_PINMUX('B', 7, AF7)>;
			};

			usart1_rx_pb15: usart1_rx_pb15 {
				pinmux = <STM32_PINMUX('B', 15, AF4)>;
			};

			usart1_rx_pz1: usart1_rx_pz1 {
				pinmux = <STM32_PINMUX('Z', 1, AF7)>;
			};

			usart1_rx_pz6: usart1_rx_pz6 {
				pinmux = <STM32_PINMUX('Z', 6, AF7)>;
			};

			usart2_rx_pa3: usart2_rx_pa3 {
				pinmux = <STM32_PINMUX('A', 3, AF7)>;
			};

			usart2_rx_pd6: usart2_rx_pd6 {
				pinmux = <STM32_PINMUX('D', 6, AF7)>;
			};

			usart2_rx_pf4: usart2_rx_pf4 {
				pinmux = <STM32_PINMUX('F', 4, AF7)>;
			};

			usart3_rx_pb11: usart3_rx_pb11 {
				pinmux = <STM32_PINMUX('B', 11, AF7)>;
			};

			usart3_rx_pb12: usart3_rx_pb12 {
				pinmux = <STM32_PINMUX('B', 12, AF8)>;
			};

			usart3_rx_pc11: usart3_rx_pc11 {
				pinmux = <STM32_PINMUX('C', 11, AF7)>;
			};

			usart3_rx_pd9: usart3_rx_pd9 {
				pinmux = <STM32_PINMUX('D', 9, AF7)>;
			};

			uart4_rx_pa1: uart4_rx_pa1 {
				pinmux = <STM32_PINMUX('A', 1, AF8)>;
			};

			uart4_rx_pa11: uart4_rx_pa11 {
				pinmux = <STM32_PINMUX('A', 11, AF6)>;
			};

			uart4_rx_pb2: uart4_rx_pb2 {
				pinmux = <STM32_PINMUX('B', 2, AF8)>;
			};

			uart4_rx_pb8: uart4_rx_pb8 {
				pinmux = <STM32_PINMUX('B', 8, AF8)>;
			};

			uart4_rx_pc11: uart4_rx_pc11 {
				pinmux = <STM32_PINMUX('C', 11, AF8)>;
			};

			uart4_rx_pd0: uart4_rx_pd0 {
				pinmux = <STM32_PINMUX('D', 0, AF8)>;
			};

			uart4_rx_pd2: uart4_rx_pd2 {
				pinmux = <STM32_PINMUX('D', 2, AF6)>;
			};

			uart4_rx_ph14: uart4_rx_ph14 {
				pinmux = <STM32_PINMUX('H', 14, AF8)>;
			};

			uart4_rx_pi9: uart4_rx_pi9 {
				pinmux = <STM32_PINMUX('I', 9, AF8)>;
			};

			uart5_rx_pb5: uart5_rx_pb5 {
				pinmux = <STM32_PINMUX('B', 5, AF12)>;
			};

			uart5_rx_pb12: uart5_rx_pb12 {
				pinmux = <STM32_PINMUX('B', 12, AF14)>;
			};

			uart5_rx_pd2: uart5_rx_pd2 {
				pinmux = <STM32_PINMUX('D', 2, AF8)>;
			};

			usart6_rx_pc7: usart6_rx_pc7 {
				pinmux = <STM32_PINMUX('C', 7, AF7)>;
			};

			usart6_rx_pg9: usart6_rx_pg9 {
				pinmux = <STM32_PINMUX('G', 9, AF7)>;
			};

			uart7_rx_pa8: uart7_rx_pa8 {
				pinmux = <STM32_PINMUX('A', 8, AF13)>;
			};

			uart7_rx_pb3: uart7_rx_pb3 {
				pinmux = <STM32_PINMUX('B', 3, AF13)>;
			};

			uart7_rx_pe7: uart7_rx_pe7 {
				pinmux = <STM32_PINMUX('E', 7, AF7)>;
			};

			uart7_rx_pf6: uart7_rx_pf6 {
				pinmux = <STM32_PINMUX('F', 6, AF7)>;
			};

			uart8_rx_pe0: uart8_rx_pe0 {
				pinmux = <STM32_PINMUX('E', 0, AF8)>;
			};

			/* UART_TX / USART_TX / LPUART_TX */

			usart1_tx_pa9: usart1_tx_pa9 {
				pinmux = <STM32_PINMUX('A', 9, AF7)>;
				bias-pull-up;
			};

			usart1_tx_pb6: usart1_tx_pb6 {
				pinmux = <STM32_PINMUX('B', 6, AF7)>;
				bias-pull-up;
			};

			usart1_tx_pb14: usart1_tx_pb14 {
				pinmux = <STM32_PINMUX('B', 14, AF4)>;
				bias-pull-up;
			};

			usart1_tx_pg11: usart1_tx_pg11 {
				pinmux = <STM32_PINMUX('G', 11, AF4)>;
				bias-pull-up;
			};

			usart1_tx_pz2: usart1_tx_pz2 {
				pinmux = <STM32_PINMUX('Z', 2, AF7)>;
				bias-pull-up;
			};

			usart1_tx_pz7: usart1_tx_pz7 {
				pinmux = <STM32_PINMUX('Z', 7, AF7)>;
				bias-pull-up;
			};

			usart2_tx_pa2: usart2_tx_pa2 {
				pinmux = <STM32_PINMUX('A', 2, AF7)>;
				bias-pull-up;
			};

			usart2_tx_pd5: usart2_tx_pd5 {
				pinmux = <STM32_PINMUX('D', 5, AF7)>;
				bias-pull-up;
			};

			usart2_tx_pf5: usart2_tx_pf5 {
				pinmux = <STM32_PINMUX('F', 5, AF7)>;
				bias-pull-up;
			};

			usart3_tx_pb10: usart3_tx_pb10 {
				pinmux = <STM32_PINMUX('B', 10, AF7)>;
				bias-pull-up;
			};

			usart3_tx_pc10: usart3_tx_pc10 {
				pinmux = <STM32_PINMUX('C', 10, AF7)>;
				bias-pull-up;
			};

			usart3_tx_pd8: usart3_tx_pd8 {
				pinmux = <STM32_PINMUX('D', 8, AF7)>;
				bias-pull-up;
			};

			uart4_tx_pa0: uart4_tx_pa0 {
				pinmux = <STM32_PINMUX('A', 0, AF8)>;
				bias-pull-up;
			};

			uart4_tx_pa12: uart4_tx_pa12 {
				pinmux = <STM32_PINMUX('A', 12, AF6)>;
				bias-pull-up;
			};

			uart4_tx_pa13: uart4_tx_pa13 {
				pinmux = <STM32_PINMUX('A', 13, AF8)>;
				bias-pull-up;
			};

			uart4_tx_pb9: uart4_tx_pb9 {
				pinmux = <STM32_PINMUX('B', 9, AF8)>;
				bias-pull-up;
			};

			uart4_tx_pc8: uart4_tx_pc8 {
				pinmux = <STM32_PINMUX('C', 8, AF6)>;
				bias-pull-up;
			};

			uart4_tx_pc10: uart4_tx_pc10 {
				pinmux = <STM32_PINMUX('C', 10, AF8)>;
				bias-pull-up;
			};

			uart4_tx_pd1: uart4_tx_pd1 {
				pinmux = <STM32_PINMUX('D', 1, AF8)>;
				bias-pull-up;
			};

			uart4_tx_pg11: uart4_tx_pg11 {
				pinmux = <STM32_PINMUX('G', 11, AF6)>;
				bias-pull-up;
			};

			uart4_tx_ph13: uart4_tx_ph13 {
				pinmux = <STM32_PINMUX('H', 13, AF8)>;
				bias-pull-up;
			};

			uart5_tx_pb6: uart5_tx_pb6 {
				pinmux = <STM32_PINMUX('B', 6, AF12)>;
				bias-pull-up;
			};

			uart5_tx_pb13: uart5_tx_pb13 {
				pinmux = <STM32_PINMUX('B', 13, AF14)>;
				bias-pull-up;
			};

			uart5_tx_pc12: uart5_tx_pc12 {
				pinmux = <STM32_PINMUX('C', 12, AF8)>;
				bias-pull-up;
			};

			usart6_tx_pc6: usart6_tx_pc6 {
				pinmux = <STM32_PINMUX('C', 6, AF7)>;
				bias-pull-up;
			};

			usart6_tx_pg14: usart6_tx_pg14 {
				pinmux = <STM32_PINMUX('G', 14, AF7)>;
				bias-pull-up;
			};

			uart7_tx_pa15: uart7_tx_pa15 {
				pinmux = <STM32_PINMUX('A', 15, AF13)>;
				bias-pull-up;
			};

			uart7_tx_pb4: uart7_tx_pb4 {
				pinmux = <STM32_PINMUX('B', 4, AF13)>;
				bias-pull-up;
			};

			uart7_tx_pe8: uart7_tx_pe8 {
				pinmux = <STM32_PINMUX('E', 8, AF7)>;
				bias-pull-up;
			};

			uart7_tx_pf7: uart7_tx_pf7 {
				pinmux = <STM32_PINMUX('F', 7, AF7)>;
				bias-pull-up;
			};

			uart8_tx_pe1: uart8_tx_pe1 {
				pinmux = <STM32_PINMUX('E', 1, AF8)>;
				bias-pull-up;
			};

			/* USB_OTG_HS */

			usb_otg_hs_sof_pa8: usb_otg_hs_sof_pa8 {
				pinmux = <STM32_PINMUX('A', 8, AF10)>;
			};

			usb_otg_hs_id_pa10: usb_otg_hs_id_pa10 {
				pinmux = <STM32_PINMUX('A', 10, ANALOG)>;
			};

		};
	};
};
